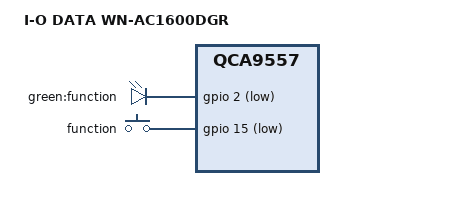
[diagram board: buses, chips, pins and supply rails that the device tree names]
// SPDX-License-Identifier: GPL-2.0-or-later OR MIT

#include "qca9557_iodata_wn-ac-dgr.dtsi"

/ {
	compatible = "iodata,wn-ac1600dgr", "qca,qca9557";
	model = "I-O DATA WN-AC1600DGR";
};

&leds {
	function {
		label = "green:function";
		gpios = <&gpio 2 GPIO_ACTIVE_LOW>;
	};
};

&keys {
	function {
		label = "function";
		gpios = <&gpio 15 GPIO_ACTIVE_LOW>;
		linux,code = <BTN_1>;
		debounce-interval = <60>;
	};
};
